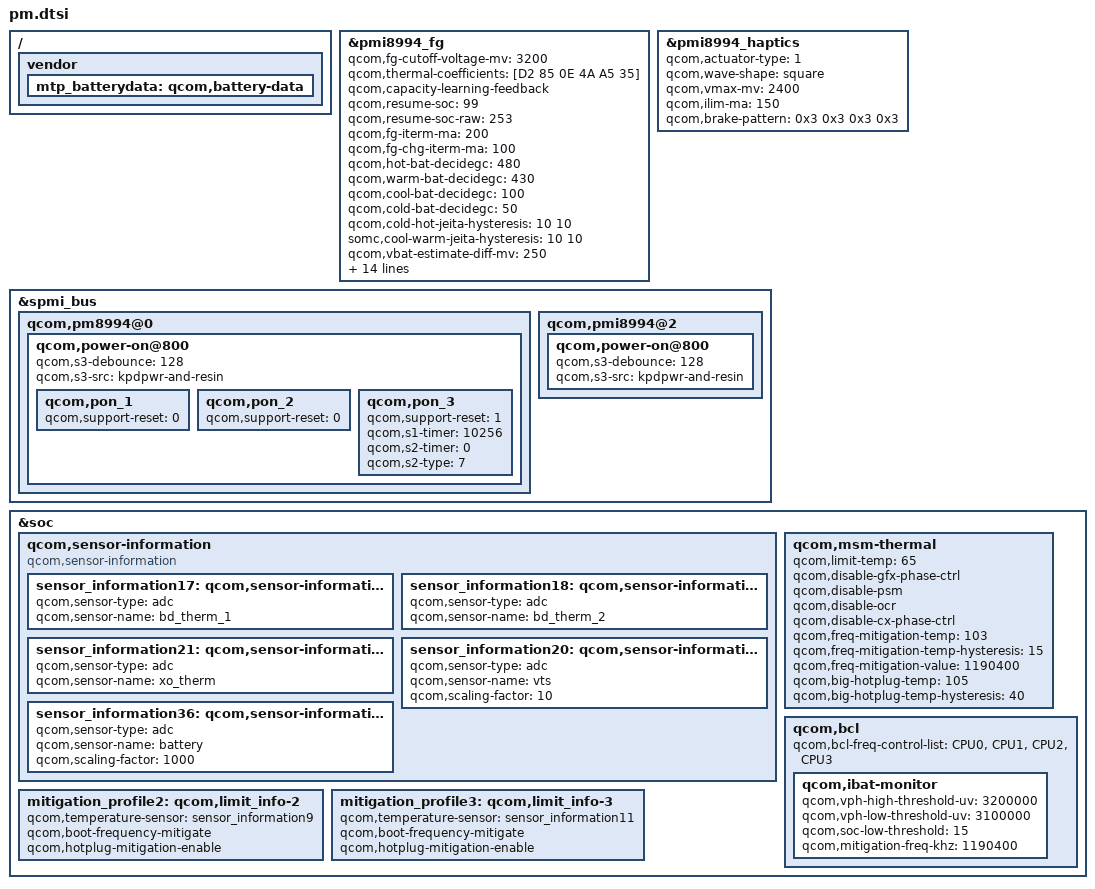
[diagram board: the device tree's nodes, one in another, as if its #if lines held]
/* Copyright (c) 2015, The Linux Foundation. All rights reserved.
 *
 * This program is free software; you can redistribute it and/or modify
 * it under the terms of the GNU General Public License version 2 and
 * only version 2 as published by the Free Software Foundation.
 *
 * This program is distributed in the hope that it will be useful,
 * but WITHOUT ANY WARRANTY; without even the implied warranty of
 * MERCHANTABILITY or FITNESS FOR A PARTICULAR PURPOSE.  See the
 * GNU General Public License for more details.
 */

/ {
	vendor {
		mtp_batterydata: qcom,battery-data {
			#include "../battery/LGE_PMI8996_2000mAh_Test_Battery_Profile_Aug26th2015_PMI8996GUI00012.dtsi"
			#include "../battery/LGE_PMI8994_2000mAh_Test_Battery_Profile_Aug26th2015_PMI8994GUI2168.dtsi"
			#include "../battery/LGE_BLT16_3000mAh_averaged_MasterSlave_Aug6th2015_PMI8994GUI2168.dtsi"
			#include "../battery/LGE_BLT16_3000mAh_averaged_MasterSlave_Aug6th2015_PMI8996GUI00012.dtsi"
			#include "../battery/LGE_BL42D1F_1600mAh_averaged_MasterSlave_Oct12th2015_PMI8996GUI1014.dtsi"
			#include "../battery/Generic_2810mAh_Sept9th2015_PMI8996GUI1004.dtsi"
			#include "../battery/LGE_BL42D1_Tocad_2800mAh_averaged_MasterSlave_Nov23rd2015_PMI8996GUI1100.dtsi"
			#include "../battery/LGE_BL42D1F_2800mAh_averaged_MasterSlave_Nov30th2015_PMI8996GUI1100.dtsi"
		};
	};
};

&pmi8994_fg {
	status = "ok";
	qcom,fg-cutoff-voltage-mv = <3200>;
	qcom,thermal-coefficients = [D2 85 0E 4A A5 35];
	qcom,capacity-learning-feedback;
	qcom,resume-soc = <99>;
	qcom,resume-soc-raw = <253>;
	qcom,fg-iterm-ma = <200>;
	qcom,fg-chg-iterm-ma = <100>;
	qcom,hot-bat-decidegc = <480>;
	qcom,warm-bat-decidegc = <430>;
	qcom,cool-bat-decidegc = <100>;
	qcom,cold-bat-decidegc = <50>;
	qcom,cold-hot-jeita-hysteresis = <10 10>;
	somc,cool-warm-jeita-hysteresis = <10 10>;
	qcom,vbat-estimate-diff-mv = <250>;
	qcom,fg-cc-cv-threshold-mv = <4340>; //float-voltage set as 4350 in common-various
	qcom,esr-pulse-tuning-en;
	qcom,fg-use-vbat-low-empty-soc;
	qcom,fg-cc-soc-limit-pct = <120>;
	qcom,fg-control-slope-limiter;
	qcom,fg-slope-limit-high-temp-chg = <6>;
	qcom,fg-slope-limit-high-temp-dischg = <6>;
	qcom,fg-slope-limit-low-temp-chg = <14>;
	qcom,fg-slope-limit-low-temp-dischg =<14>;
	qcom,fg-dischg-voltage-gain-ctrl;
	qcom,fg-dischg-voltage-gain-soc = <7 15 20>;
	qcom,fg-dischg-med-voltage-gain = <5 4 4>;
	qcom,fg-dischg-high-voltage-gain = <4 4 3>;
	qcom,cl-max-limit-deciperc= <50>;
};

&pmi8994_haptics {
	status = "okay";
	qcom,actuator-type = <1>;
	qcom,wave-shape = "square";
	qcom,vmax-mv = <2400>;
	qcom,ilim-ma = <150>;
	qcom,brake-pattern = <0x3 0x3 0x3 0x3>;
};

&spmi_bus {
	qcom,pm8994@0 {
		 qcom,power-on@800 {
			 qcom,s3-debounce = <128>;
			 qcom,s3-src = "kpdpwr-and-resin";
			 qcom,pon_1 {  /* KPD_PWR_N */
				  status = "ok";
				  qcom,support-reset = <0>;
			 };
			 qcom,pon_2 {  /* RESIN_N */
				  status = "ok";
				  qcom,support-reset = <0>;
			 };
			 qcom,pon_3 {  /* KPD_PWR_N AND RESIN_N */
				  status = "ok";
#ifdef CONFIG_MACH_MSM8996_H1_VZW
				  qcom,support-reset = <1>;
				  qcom,s1-timer = <10256>;
				  qcom,s2-timer = <0>;
				  qcom,s2-type = <7>;
#else
				  qcom,support-reset = <0>;
#endif
			 };
		 };
	};

	qcom,pmi8994@2 {
		qcom,power-on@800 {
			qcom,s3-debounce = <128>;
			qcom,s3-src = "kpdpwr-and-resin";
		};
	};
};

&soc {
	qcom,sensor-information {
		compatible = "qcom,sensor-information";

		sensor_information17: qcom,sensor-information-17 {
			qcom,sensor-type = "adc";
			qcom,sensor-name = "bd_therm_1";
		};

		sensor_information18: qcom,sensor-information-18 {
			qcom,sensor-type = "adc";
			qcom,sensor-name = "bd_therm_2";
		};

		sensor_information21: qcom,sensor-information-21 {
			qcom,sensor-type = "adc";
			qcom,sensor-name = "xo_therm";
		};
		sensor_information20: qcom,sensor-information-20 {
			qcom,sensor-type = "adc";
			qcom,sensor-name = "vts";
			qcom,scaling-factor = <10>;
		};
		sensor_information36: qcom,sensor-information-36 {
			qcom,sensor-type = "adc";
			qcom,sensor-name = "battery";
			qcom,scaling-factor = <1000>;
		};
	};

	mitigation_profile2: qcom,limit_info-2 {
		qcom,temperature-sensor = <&sensor_information9>;
		qcom,boot-frequency-mitigate;
		qcom,hotplug-mitigation-enable;
	};

	mitigation_profile3: qcom,limit_info-3 {
		qcom,temperature-sensor = <&sensor_information11>;
		qcom,boot-frequency-mitigate;
		qcom,hotplug-mitigation-enable;
	};

	qcom,msm-thermal {
		qcom,limit-temp = <65>;
		qcom,disable-gfx-phase-ctrl;
		qcom,disable-psm;
		qcom,disable-ocr;
		qcom,disable-cx-phase-ctrl;
		qcom,freq-mitigation-temp = <103>;
		qcom,freq-mitigation-temp-hysteresis = <15>;
		qcom,freq-mitigation-value = <1190400>;
		qcom,big-hotplug-temp = <105>;
		qcom,big-hotplug-temp-hysteresis = <40>;
	};

	qcom,bcl {
		/delete-property/ qcom,bcl-soc-hotplug-list;
		qcom,bcl-freq-control-list = <&CPU0 &CPU1 &CPU2 &CPU3>;
		qcom,ibat-monitor {
			qcom,vph-high-threshold-uv = <3200000>;
			qcom,vph-low-threshold-uv = <3100000>;
			qcom,soc-low-threshold = <15>;
			qcom,mitigation-freq-khz = <1190400>;
		};
	};
};
